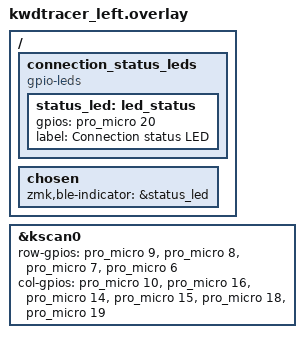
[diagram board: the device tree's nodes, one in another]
#include "kwdtracer.dtsi" // The shared dtsi file is included in the overlay

// Label of the kscan node in the dtsi
&kscan0 {
    row-gpios
        = <&pro_micro 9 (GPIO_ACTIVE_HIGH | GPIO_PULL_DOWN)>
        , <&pro_micro 8 (GPIO_ACTIVE_HIGH | GPIO_PULL_DOWN)>
        , <&pro_micro 7 (GPIO_ACTIVE_HIGH | GPIO_PULL_DOWN)>
        , <&pro_micro 6 (GPIO_ACTIVE_HIGH | GPIO_PULL_DOWN)>
        ;
    col-gpios
        = <&pro_micro 10 GPIO_ACTIVE_HIGH>
        , <&pro_micro 16 GPIO_ACTIVE_HIGH>
        , <&pro_micro 14 GPIO_ACTIVE_HIGH>
        , <&pro_micro 15 GPIO_ACTIVE_HIGH>
        , <&pro_micro 18 GPIO_ACTIVE_HIGH>
        , <&pro_micro 19 GPIO_ACTIVE_HIGH>
        ;
};

/ {
    connection_status_leds {
        compatible = "gpio-leds";
        status_led: led_status {
            gpios = <&pro_micro 20 GPIO_ACTIVE_HIGH>;
            label = "Connection status LED";
        };
    };
};

/ {
    chosen {
        zmk,ble-indicator = &status_led;
    };
};
